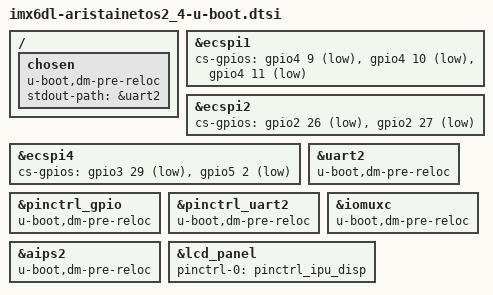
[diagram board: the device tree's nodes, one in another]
// SPDX-License-Identifier: GPL-2.0+ or X11
/*
 * Copyright (C) 2019 Heiko Schocher <hs@denx.de>
 */

/ {
	chosen {
		u-boot,dm-pre-reloc;
		stdout-path = &uart2;
	};
};

&ecspi1 {
	cs-gpios = <&gpio4 9 GPIO_ACTIVE_LOW
		    &gpio4 10 GPIO_ACTIVE_LOW
		    &gpio4 11 GPIO_ACTIVE_LOW>;
};

&ecspi2 {
	cs-gpios = <&gpio2 26 GPIO_ACTIVE_LOW &gpio2 27 GPIO_ACTIVE_LOW>;
};

&ecspi4 {
	cs-gpios = <&gpio3 29 GPIO_ACTIVE_LOW &gpio5 2 GPIO_ACTIVE_LOW>;
};

&uart2 {
	u-boot,dm-pre-reloc;
};

&pinctrl_gpio {
	u-boot,dm-pre-reloc;
};

&pinctrl_uart2 {
	u-boot,dm-pre-reloc;
};

&iomuxc {
	u-boot,dm-pre-reloc;
};

&aips2 {
	u-boot,dm-pre-reloc;
};

&lcd_panel {
	pinctrl-names = "default";
	pinctrl-0 = <&pinctrl_ipu_disp>;
};
